# Qorvo_SVD register map
Vendor: Qorvo Inc; Series: ARMCM4; File version: 1.0
Registers are 8-bit, read-write, reset 0x0 unless marked. A register's access mark holds for its fields unless they carry their own. Offsets are from the block's base; [hi:lo] are bit positions; {n}, {i} and the like mark numbered series.

## INT_CTRL
Base 0x40000B00
0x00 INT_CTRL_GLOBAL_INTERRUPTS_ENABLE
  [0] GLOBAL_INTERRUPTS_ENABLE — This bit enables the external interrupts
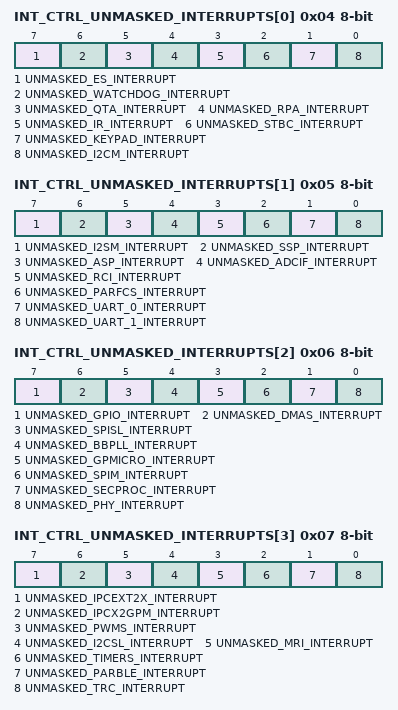
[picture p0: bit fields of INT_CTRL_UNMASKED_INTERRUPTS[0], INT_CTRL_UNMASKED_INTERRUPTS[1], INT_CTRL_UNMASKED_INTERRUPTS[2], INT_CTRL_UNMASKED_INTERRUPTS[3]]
0x04 INT_CTRL_UNMASKED_INTERRUPTS[0] ro
  [7] UNMASKED_ES_INTERRUPT
  [6] UNMASKED_WATCHDOG_INTERRUPT
  [5] UNMASKED_QTA_INTERRUPT — unmasked qta interrupt (same for internal and external)
  [4] UNMASKED_RPA_INTERRUPT — unmasked RPA accelerator interrupt
  [3] UNMASKED_IR_INTERRUPT — unmasked IR driver interrupt
  [2] UNMASKED_STBC_INTERRUPT — unmasked standby controller interrupt (internal and external are the same)
  [1] UNMASKED_KEYPAD_INTERRUPT — unmasked KeyPad Scan interrupt
  [0] UNMASKED_I2CM_INTERRUPT — unmasked I2C master interrupt
0x05 INT_CTRL_UNMASKED_INTERRUPTS[1] ro
  [7] UNMASKED_I2SM_INTERRUPT — unmasked I2S master interrupt
  [6] UNMASKED_SSP_INTERRUPT — unmasked security processor interrupt
  [5] UNMASKED_ASP_INTERRUPT — unmasked ASP interface interrupt
  [4] UNMASKED_ADCIF_INTERRUPT — unmasked ADC interface interrupt
  [3] UNMASKED_RCI_INTERRUPT
  [2] UNMASKED_PARFCS_INTERRUPT — unmasked parfcs filter interrupt (same for internal and external)
  [1] UNMASKED_UART_0_INTERRUPT — unmasked UART interrupt
  [0] UNMASKED_UART_1_INTERRUPT — unmasked UART interrupt
0x06 INT_CTRL_UNMASKED_INTERRUPTS[2] ro
  [7] UNMASKED_GPIO_INTERRUPT — unmasked gpio external interrupt
  [6] UNMASKED_DMAS_INTERRUPT — unmasked DMA SCB engine interrupt
  [5] UNMASKED_SPISL_INTERRUPT — unmasked SPI Slave interrupt
  [4] UNMASKED_BBPLL_INTERRUPT
  [3] UNMASKED_GPMICRO_INTERRUPT
  [2] UNMASKED_SPIM_INTERRUPT — unmasked SPI Master interrupt
  [1] UNMASKED_SECPROC_INTERRUPT — unmasked Security Processor interrupt
  [0] UNMASKED_PHY_INTERRUPT
0x07 INT_CTRL_UNMASKED_INTERRUPTS[3] ro
  [7] UNMASKED_IPCEXT2X_INTERRUPT — unmasked inter process communication interrupt (ext 2 ...)
  [6] UNMASKED_IPCX2GPM_INTERRUPT — unmasked inter process communication interrupt (... 2 gpm)
  [5] UNMASKED_PWMS_INTERRUPT — unmasked PWM interrupt
  [4] UNMASKED_I2CSL_INTERRUPT — unmasked I2C Slave interrupt
  [3] UNMASKED_MRI_INTERRUPT — unmasked mri interrupt (internal and external are the same)
  [2] UNMASKED_TIMERS_INTERRUPT — unmasked timer interrupt
  [1] UNMASKED_PARBLE_INTERRUPT — unmasked parble filter interrupt (same for internal and external)
  [0] UNMASKED_TRC_INTERRUPT — unmasked trc interrupt (same for internal and external)
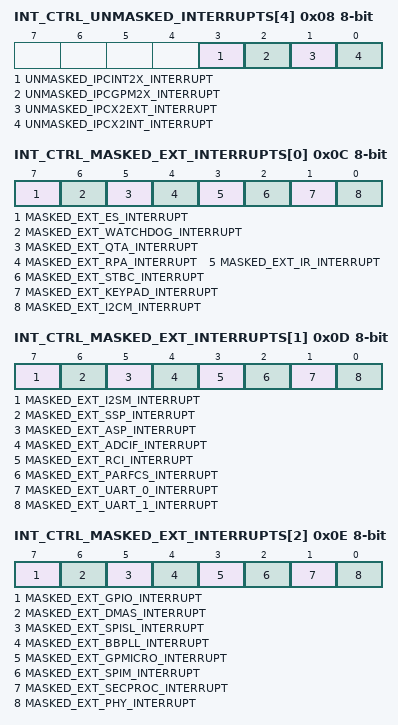
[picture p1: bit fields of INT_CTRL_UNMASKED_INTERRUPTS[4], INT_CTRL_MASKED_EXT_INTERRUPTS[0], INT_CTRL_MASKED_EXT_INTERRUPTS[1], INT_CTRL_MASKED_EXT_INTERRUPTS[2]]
0x08 INT_CTRL_UNMASKED_INTERRUPTS[4] ro
  [3] UNMASKED_IPCINT2X_INTERRUPT — unmasked inter process communication interrupt (int 2 ...)
  [2] UNMASKED_IPCGPM2X_INTERRUPT — unmasked inter process communication interrupt (gpm 2 ...)
  [1] UNMASKED_IPCX2EXT_INTERRUPT — unmasked inter process communication interrupt (... 2 ext)
  [0] UNMASKED_IPCX2INT_INTERRUPT — unmasked inter process communication interrupt (... 2 int)
0x0C INT_CTRL_MASKED_EXT_INTERRUPTS[0] ro
  [7] MASKED_EXT_ES_INTERRUPT — masked external ES interrupt
  [6] MASKED_EXT_WATCHDOG_INTERRUPT — masked external watchdog interrupt
  [5] MASKED_EXT_QTA_INTERRUPT — masked external qta interrupt (same for internal and external)
  [4] MASKED_EXT_RPA_INTERRUPT — masked external RPA accelerator interrupt
  [3] MASKED_EXT_IR_INTERRUPT — masked external IR driver interrupt
  [2] MASKED_EXT_STBC_INTERRUPT — masked external standby controller interrupt (internal and external are the same)
  [1] MASKED_EXT_KEYPAD_INTERRUPT — masked external KeyPad Scan interrupt
  [0] MASKED_EXT_I2CM_INTERRUPT — masked external I2C master interrupt
0x0D INT_CTRL_MASKED_EXT_INTERRUPTS[1] ro
  [7] MASKED_EXT_I2SM_INTERRUPT — masked external I2S master interrupt
  [6] MASKED_EXT_SSP_INTERRUPT — masked external security processor interrupt
  [5] MASKED_EXT_ASP_INTERRUPT — masked external ASP interface interrupt
  [4] MASKED_EXT_ADCIF_INTERRUPT — masked external ADC interface interrupt
  [3] MASKED_EXT_RCI_INTERRUPT — masked external RCI interrupt
  [2] MASKED_EXT_PARFCS_INTERRUPT — masked external parfcs filter interrupt (same for internal and external)
  [1] MASKED_EXT_UART_0_INTERRUPT — masked external UART interrupt
  [0] MASKED_EXT_UART_1_INTERRUPT — masked external UART interrupt
0x0E INT_CTRL_MASKED_EXT_INTERRUPTS[2] ro
  [7] MASKED_EXT_GPIO_INTERRUPT — masked external gpio external interrupt
  [6] MASKED_EXT_DMAS_INTERRUPT — masked external DMA SCB engine interrupt
  [5] MASKED_EXT_SPISL_INTERRUPT — masked external SPI Slave interrupt
  [4] MASKED_EXT_BBPLL_INTERRUPT — masked external BBPLL interrupt
  [3] MASKED_EXT_GPMICRO_INTERRUPT — masked external gpmicro interrupt
  [2] MASKED_EXT_SPIM_INTERRUPT — masked external SPI Master interrupt
  [1] MASKED_EXT_SECPROC_INTERRUPT — masked external Security Processor interrupt
  [0] MASKED_EXT_PHY_INTERRUPT — masked external Phy interrupt
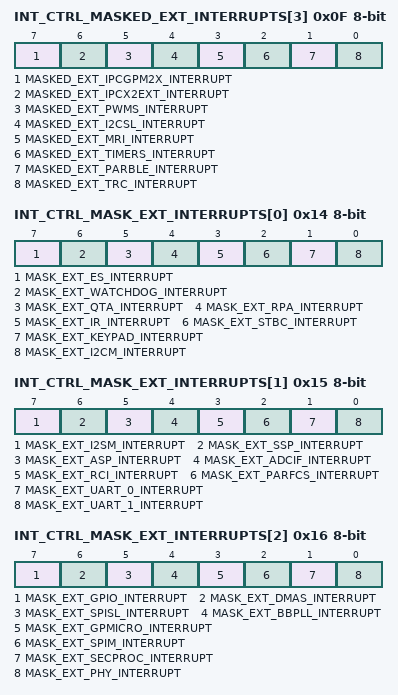
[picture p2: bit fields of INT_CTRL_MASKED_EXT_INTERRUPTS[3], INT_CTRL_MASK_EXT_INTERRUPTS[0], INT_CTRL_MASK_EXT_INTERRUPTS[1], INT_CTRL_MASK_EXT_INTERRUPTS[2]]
0x0F INT_CTRL_MASKED_EXT_INTERRUPTS[3] ro
  [7] MASKED_EXT_IPCGPM2X_INTERRUPT — masked external inter process communication interrupt (gpm 2 ...)
  [6] MASKED_EXT_IPCX2EXT_INTERRUPT — masked external inter process communication interrupt (... 2 ext)
  [5] MASKED_EXT_PWMS_INTERRUPT — masked external PWM interrupt
  [4] MASKED_EXT_I2CSL_INTERRUPT — masked external I2C Slave interrupt
  [3] MASKED_EXT_MRI_INTERRUPT — masked external mri interrupt (internal and external are the same)
  [2] MASKED_EXT_TIMERS_INTERRUPT — masked external timer interrupt
  [1] MASKED_EXT_PARBLE_INTERRUPT — masked external parble filter interrupt (same for internal and external)
  [0] MASKED_EXT_TRC_INTERRUPT — masked external trc interrupt (same for internal and external)
0x10 INT_CTRL_MASKED_EXT_INTERRUPTS[4] ro
  [0] MASKED_EXT_IPCINT2X_INTERRUPT — masked external inter process communication interrupt (int 2 ...)
0x14 INT_CTRL_MASK_EXT_INTERRUPTS[0]
  [7] MASK_EXT_ES_INTERRUPT — mask external ES interrupt
  [6] MASK_EXT_WATCHDOG_INTERRUPT — mask external watchdog interrupt
  [5] MASK_EXT_QTA_INTERRUPT — mask external qta interrupt (same for internal and external)
  [4] MASK_EXT_RPA_INTERRUPT — mask external RPA accelerator interrupt
  [3] MASK_EXT_IR_INTERRUPT — mask external IR driver interrupt
  [2] MASK_EXT_STBC_INTERRUPT — mask external standby controller interrupt (internal and external are the same)
  [1] MASK_EXT_KEYPAD_INTERRUPT — mask external KeyPad Scan interrupt
  [0] MASK_EXT_I2CM_INTERRUPT — mask external I2C master interrupt
0x15 INT_CTRL_MASK_EXT_INTERRUPTS[1]
  [7] MASK_EXT_I2SM_INTERRUPT — mask external I2S master interrupt
  [6] MASK_EXT_SSP_INTERRUPT — mask external security processor interrupt
  [5] MASK_EXT_ASP_INTERRUPT — mask external ASP interface interrupt
  [4] MASK_EXT_ADCIF_INTERRUPT — mask external ADC interface interrupt
  [3] MASK_EXT_RCI_INTERRUPT — mask external RCI interrupt
  [2] MASK_EXT_PARFCS_INTERRUPT — mask external parfcs filter interrupt (same for internal and external)
  [1] MASK_EXT_UART_0_INTERRUPT — mask external UART interrupt
  [0] MASK_EXT_UART_1_INTERRUPT — mask external UART interrupt
0x16 INT_CTRL_MASK_EXT_INTERRUPTS[2]
  [7] MASK_EXT_GPIO_INTERRUPT — mask external gpio external interrupt
  [6] MASK_EXT_DMAS_INTERRUPT — mask external DMA SCB engine interrupt
  [5] MASK_EXT_SPISL_INTERRUPT — mask external SPI Slave interrupt
  [4] MASK_EXT_BBPLL_INTERRUPT — mask external BBPLL interrupt
  [3] MASK_EXT_GPMICRO_INTERRUPT — mask external gpmicro interrupt
  [2] MASK_EXT_SPIM_INTERRUPT — mask external SPI Master interrupt
  [1] MASK_EXT_SECPROC_INTERRUPT — mask external Security Processor interrupt
  [0] MASK_EXT_PHY_INTERRUPT — mask external Phy interrupt
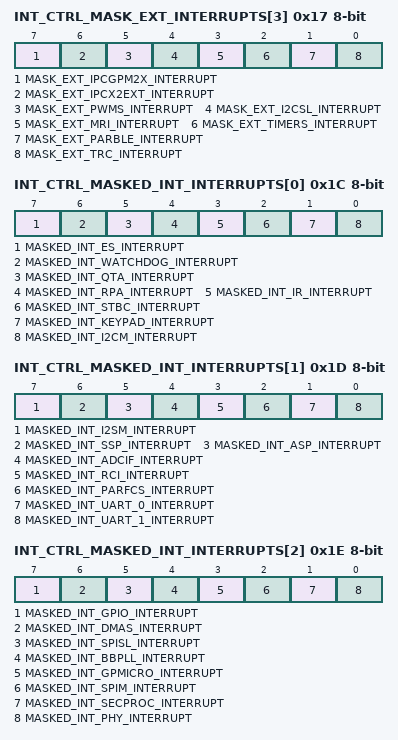
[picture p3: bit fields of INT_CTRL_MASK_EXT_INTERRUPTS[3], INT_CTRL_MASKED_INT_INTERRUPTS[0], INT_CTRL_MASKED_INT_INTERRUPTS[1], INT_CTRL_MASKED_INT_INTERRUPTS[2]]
0x17 INT_CTRL_MASK_EXT_INTERRUPTS[3]
  [7] MASK_EXT_IPCGPM2X_INTERRUPT — mask external inter process communication interrupt (gpm 2 ...)
  [6] MASK_EXT_IPCX2EXT_INTERRUPT — mask external inter process communication interrupt (... 2 ext)
  [5] MASK_EXT_PWMS_INTERRUPT — mask external PWM interrupt
  [4] MASK_EXT_I2CSL_INTERRUPT — mask external I2C Slave interrupt
  [3] MASK_EXT_MRI_INTERRUPT — mask external mri interrupt (internal and external are the same)
  [2] MASK_EXT_TIMERS_INTERRUPT — mask external timer interrupt
  [1] MASK_EXT_PARBLE_INTERRUPT — mask external parble filter interrupt (same for internal and external)
  [0] MASK_EXT_TRC_INTERRUPT — mask external trc interrupt (same for internal and external)
0x18 INT_CTRL_MASK_EXT_INTERRUPTS[4]
  [0] MASK_EXT_IPCINT2X_INTERRUPT — mask external inter process communication interrupt (int 2 ...)
0x1C INT_CTRL_MASKED_INT_INTERRUPTS[0] ro
  [7] MASKED_INT_ES_INTERRUPT — masked internal ES interrupt
  [6] MASKED_INT_WATCHDOG_INTERRUPT — masked internal watchdog interrupt
  [5] MASKED_INT_QTA_INTERRUPT — masked internal qta interrupt (same for internal and external)
  [4] MASKED_INT_RPA_INTERRUPT — masked internal RPA accelerator interrupt
  [3] MASKED_INT_IR_INTERRUPT — masked internal IR driver interrupt
  [2] MASKED_INT_STBC_INTERRUPT — masked internal standby controller interrupt (internal and external are the same)
  [1] MASKED_INT_KEYPAD_INTERRUPT — masked internal KeyPad Scan interrupt
  [0] MASKED_INT_I2CM_INTERRUPT — masked internal I2C master interrupt
0x1D INT_CTRL_MASKED_INT_INTERRUPTS[1] ro
  [7] MASKED_INT_I2SM_INTERRUPT — masked internal I2S master interrupt
  [6] MASKED_INT_SSP_INTERRUPT — masked internal security processor interrupt
  [5] MASKED_INT_ASP_INTERRUPT — masked internal ASP interface interrupt
  [4] MASKED_INT_ADCIF_INTERRUPT — masked internal ADC interface interrupt
  [3] MASKED_INT_RCI_INTERRUPT — masked internal RCI interrupt
  [2] MASKED_INT_PARFCS_INTERRUPT — masked internal parfcs filter interrupt (same for internal and external)
  [1] MASKED_INT_UART_0_INTERRUPT — masked internal UART interrupt
  [0] MASKED_INT_UART_1_INTERRUPT — masked internal UART interrupt
0x1E INT_CTRL_MASKED_INT_INTERRUPTS[2] ro
  [7] MASKED_INT_GPIO_INTERRUPT — masked internal gpio external interrupt
  [6] MASKED_INT_DMAS_INTERRUPT — masked internal DMA SCB engine interrupt
  [5] MASKED_INT_SPISL_INTERRUPT — masked internal SPI Slave interrupt
  [4] MASKED_INT_BBPLL_INTERRUPT — masked internal BBPLL interrupt
  [3] MASKED_INT_GPMICRO_INTERRUPT — masked internal gpmicro interrupt
  [2] MASKED_INT_SPIM_INTERRUPT — masked internal SPI Master interrupt
  [1] MASKED_INT_SECPROC_INTERRUPT — masked internal Security Processor interrupt
  [0] MASKED_INT_PHY_INTERRUPT — masked internal Phy interrupt
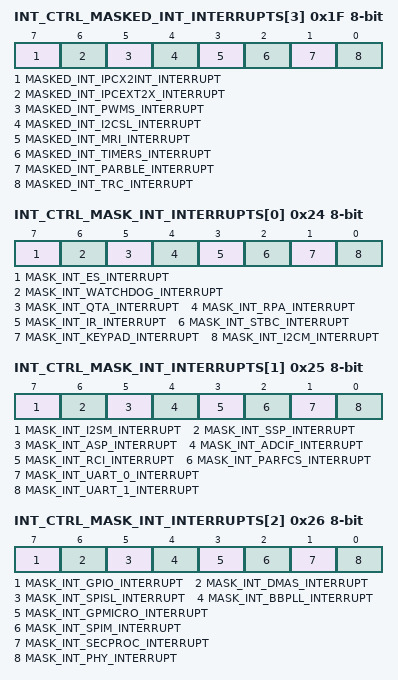
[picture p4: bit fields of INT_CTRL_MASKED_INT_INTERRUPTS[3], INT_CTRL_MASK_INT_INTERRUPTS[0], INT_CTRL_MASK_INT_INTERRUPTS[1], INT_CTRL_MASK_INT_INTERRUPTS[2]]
0x1F INT_CTRL_MASKED_INT_INTERRUPTS[3] ro
  [7] MASKED_INT_IPCX2INT_INTERRUPT — masked internal inter process communication interrupt (... 2 int)
  [6] MASKED_INT_IPCEXT2X_INTERRUPT — masked internal inter process communication interrupt (ext 2 ...)
  [5] MASKED_INT_PWMS_INTERRUPT — masked internal PWM interrupt
  [4] MASKED_INT_I2CSL_INTERRUPT — masked internal I2C Slave interrupt
  [3] MASKED_INT_MRI_INTERRUPT — masked internal mri interrupt (internal and external are the same)
  [2] MASKED_INT_TIMERS_INTERRUPT — masked internal timer interrupt
  [1] MASKED_INT_PARBLE_INTERRUPT — masked internal parble filter interrupt (same for internal and external)
  [0] MASKED_INT_TRC_INTERRUPT — masked internal trc interrupt (same for internal and external)
0x20 INT_CTRL_MASKED_INT_INTERRUPTS[4] ro
  [0] MASKED_INT_IPCGPM2X_INTERRUPT — masked internal inter process communication interrupt (gpm 2 ...)
0x24 INT_CTRL_MASK_INT_INTERRUPTS[0]
  [7] MASK_INT_ES_INTERRUPT — mask internal ES interrupt
  [6] MASK_INT_WATCHDOG_INTERRUPT — mask internal watchdog interrupt
  [5] MASK_INT_QTA_INTERRUPT — mask internal qta interrupt (same for internal and external)
  [4] MASK_INT_RPA_INTERRUPT — mask internal RPA accelerator interrupt
  [3] MASK_INT_IR_INTERRUPT — mask internal IR driver interrupt
  [2] MASK_INT_STBC_INTERRUPT — mask internal standby controller interrupt (internal and external are the same)
  [1] MASK_INT_KEYPAD_INTERRUPT — mask internal KeyPad Scan interrupt
  [0] MASK_INT_I2CM_INTERRUPT — mask internal I2C master interrupt
0x25 INT_CTRL_MASK_INT_INTERRUPTS[1]
  [7] MASK_INT_I2SM_INTERRUPT — mask internal I2S master interrupt
  [6] MASK_INT_SSP_INTERRUPT — mask internal security processor interrupt
  [5] MASK_INT_ASP_INTERRUPT — mask internal ASP interface interrupt
  [4] MASK_INT_ADCIF_INTERRUPT — mask internal ADC interface interrupt
  [3] MASK_INT_RCI_INTERRUPT — mask internal RCI interrupt
  [2] MASK_INT_PARFCS_INTERRUPT — mask internal parfcs filter interrupt (same for internal and external)
  [1] MASK_INT_UART_0_INTERRUPT — mask internal UART interrupt
  [0] MASK_INT_UART_1_INTERRUPT — mask internal UART interrupt
0x26 INT_CTRL_MASK_INT_INTERRUPTS[2]
  [7] MASK_INT_GPIO_INTERRUPT — mask internal gpio external interrupt
  [6] MASK_INT_DMAS_INTERRUPT — mask internal DMA SCB engine interrupt
  [5] MASK_INT_SPISL_INTERRUPT — mask internal SPI Slave interrupt
  [4] MASK_INT_BBPLL_INTERRUPT — mask internal BBPLL interrupt
  [3] MASK_INT_GPMICRO_INTERRUPT — mask internal gpmicro interrupt
  [2] MASK_INT_SPIM_INTERRUPT — mask internal SPI Master interrupt
  [1] MASK_INT_SECPROC_INTERRUPT — mask internal Security Processor interrupt
  [0] MASK_INT_PHY_INTERRUPT — mask internal Phy interrupt
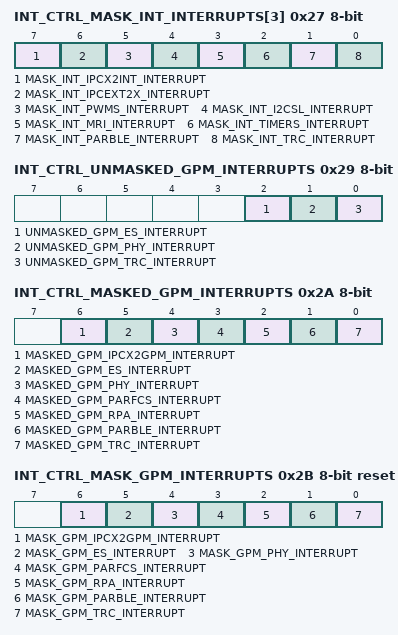
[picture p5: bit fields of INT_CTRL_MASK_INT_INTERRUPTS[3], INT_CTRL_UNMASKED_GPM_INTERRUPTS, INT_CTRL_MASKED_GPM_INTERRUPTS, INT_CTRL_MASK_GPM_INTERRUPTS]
0x27 INT_CTRL_MASK_INT_INTERRUPTS[3]
  [7] MASK_INT_IPCX2INT_INTERRUPT — mask internal inter process communication interrupt (... 2 int)
  [6] MASK_INT_IPCEXT2X_INTERRUPT — mask internal inter process communication interrupt (ext 2 ...)
  [5] MASK_INT_PWMS_INTERRUPT — mask internal PWM interrupt
  [4] MASK_INT_I2CSL_INTERRUPT — mask internal I2C Slave interrupt
  [3] MASK_INT_MRI_INTERRUPT — mask internal mri interrupt (internal and external are the same)
  [2] MASK_INT_TIMERS_INTERRUPT — mask internal timer interrupt
  [1] MASK_INT_PARBLE_INTERRUPT — mask internal parble filter interrupt (same for internal and external)
  [0] MASK_INT_TRC_INTERRUPT — mask internal trc interrupt (same for internal and external)
0x28 INT_CTRL_MASK_INT_INTERRUPTS[4]
  [0] MASK_INT_IPCGPM2X_INTERRUPT — mask internal inter process communication interrupt (gpm 2 ...)
0x29 INT_CTRL_UNMASKED_GPM_INTERRUPTS ro
  [2] UNMASKED_GPM_ES_INTERRUPT — unmasked ES interrupt for gpmicro
  [1] UNMASKED_GPM_PHY_INTERRUPT — unmasked Phy interrupt for gpmicro
  [0] UNMASKED_GPM_TRC_INTERRUPT — unmasked trc interrupt for gpmicro
0x2A INT_CTRL_MASKED_GPM_INTERRUPTS ro
  [6] MASKED_GPM_IPCX2GPM_INTERRUPT — masked inter process communication interrupt (... 2 gpm) for gpmicro
  [5] MASKED_GPM_ES_INTERRUPT — masked ES interrupt for gpmicro
  [4] MASKED_GPM_PHY_INTERRUPT — masked Phy interrupt for gpmicro
  [3] MASKED_GPM_PARFCS_INTERRUPT — masked parfcs filter interrupt for gpmicro
  [2] MASKED_GPM_RPA_INTERRUPT — masked RPA accelerator interrupt for gpmicro
  [1] MASKED_GPM_PARBLE_INTERRUPT — masked parble filter interrupt for gpmicro
  [0] MASKED_GPM_TRC_INTERRUPT — masked trc interrupt for gpmicro
0x2B INT_CTRL_MASK_GPM_INTERRUPTS reset 0x1A
  [6] MASK_GPM_IPCX2GPM_INTERRUPT — mask inter process communication interrupt (... 2 gpm) for gpmicro
  [5] MASK_GPM_ES_INTERRUPT — mask ES interrupt for gpmicro
  [4] MASK_GPM_PHY_INTERRUPT — mask Phy interrupt for gpmicro
  [3] MASK_GPM_PARFCS_INTERRUPT — mask parfcs filter interrupt for gpmicro
  [2] MASK_GPM_RPA_INTERRUPT — mask RPA accelerator interrupt for gpmicro
  [1] MASK_GPM_PARBLE_INTERRUPT — mask parble filter interrupt for gpmicro
  [0] MASK_GPM_TRC_INTERRUPT — mask trc interrupt for gpmicro
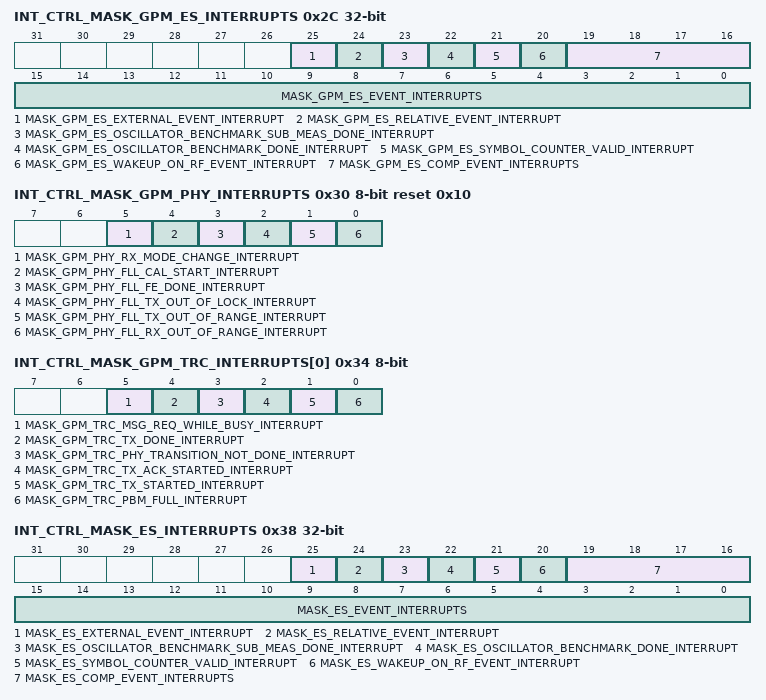
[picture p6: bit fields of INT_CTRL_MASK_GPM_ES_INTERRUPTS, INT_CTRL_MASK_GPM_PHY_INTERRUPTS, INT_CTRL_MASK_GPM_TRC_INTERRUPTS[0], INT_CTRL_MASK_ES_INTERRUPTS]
0x2C INT_CTRL_MASK_GPM_ES_INTERRUPTS 32-bit
  [25] MASK_GPM_ES_EXTERNAL_EVENT_INTERRUPT — masks the External Event Interrupt
  [24] MASK_GPM_ES_RELATIVE_EVENT_INTERRUPT — masks the es Relative Event Interrupt
  [23] MASK_GPM_ES_OSCILLATOR_BENCHMARK_SUB_MEAS_DONE_INTERRUPT — masks the es oscillator benchmark sub measurement done interrupt
  [22] MASK_GPM_ES_OSCILLATOR_BENCHMARK_DONE_INTERRUPT — masks the es oscillator benchmark interrupt
  [21] MASK_GPM_ES_SYMBOL_COUNTER_VALID_INTERRUPT — masks the es symbol counter interrupt
  [20] MASK_GPM_ES_WAKEUP_ON_RF_EVENT_INTERRUPT — masks the Wakeup_on_rf Event interrupt
  [19:16] MASK_GPM_ES_COMP_EVENT_INTERRUPTS — masks the Comparator Event interrupts
  [15:0] MASK_GPM_ES_EVENT_INTERRUPTS — masks the Event Interrupts
0x30 INT_CTRL_MASK_GPM_PHY_INTERRUPTS reset 0x10
  [5] MASK_GPM_PHY_RX_MODE_CHANGE_INTERRUPT — masks the interrupt for rx_mode changes
  [4] MASK_GPM_PHY_FLL_CAL_START_INTERRUPT — masks the interrupt for the fll fp out of range event
  [3] MASK_GPM_PHY_FLL_FE_DONE_INTERRUPT — masks the interrupt for the fll fp out of range event
  [2] MASK_GPM_PHY_FLL_TX_OUT_OF_LOCK_INTERRUPT — masks the interrupt for the fll tx_out of lock event
  [1] MASK_GPM_PHY_FLL_TX_OUT_OF_RANGE_INTERRUPT — masks the interrupt for the fll tx out of range event
  [0] MASK_GPM_PHY_FLL_RX_OUT_OF_RANGE_INTERRUPT — masks the interrupt for the fll rx out of range event
0x34 INT_CTRL_MASK_GPM_TRC_INTERRUPTS[0]
  [5] MASK_GPM_TRC_MSG_REQ_WHILE_BUSY_INTERRUPT, [4] MASK_GPM_TRC_TX_DONE_INTERRUPT, [3] MASK_GPM_TRC_PHY_TRANSITION_NOT_DONE_INTERRUPT, [2] MASK_GPM_TRC_TX_ACK_STARTED_INTERRUPT, [1] MASK_GPM_TRC_TX_STARTED_INTERRUPT, [0] MASK_GPM_TRC_PBM_FULL_INTERRUPT
0x35 INT_CTRL_MASK_GPM_TRC_INTERRUPTS[1]
  [n] MASK_GPM_TRC_CAL_DONE_CH{n}_INTERRUPT (n=0..5), [5:0] MASK_GPM_TRC_CAL_DONE_INTERRUPTS
0x36 INT_CTRL_MASK_GPM_TRC_INTERRUPTS[2]
  [n] MASK_GPM_TRC_RX_WINDOW_DONE_CH{n}_INTERRUPT (n=0..5), [5:0] MASK_GPM_TRC_RX_WINDOW_DONE_INTERRUPTS
0x38 INT_CTRL_MASK_ES_INTERRUPTS 32-bit
  [25] MASK_ES_EXTERNAL_EVENT_INTERRUPT — masks the External Event Interrupt
  [24] MASK_ES_RELATIVE_EVENT_INTERRUPT — masks the es Relative Event Interrupt
  [23] MASK_ES_OSCILLATOR_BENCHMARK_SUB_MEAS_DONE_INTERRUPT — masks the es oscillator benchmark sub meas done interrupt
  [22] MASK_ES_OSCILLATOR_BENCHMARK_DONE_INTERRUPT — masks the es oscillator benchmark interrupt
  [21] MASK_ES_SYMBOL_COUNTER_VALID_INTERRUPT — masks the es symbol counter interrupt
  [20] MASK_ES_WAKEUP_ON_RF_EVENT_INTERRUPT — masks the Wakeup_on_rf Event interrupt
  [19:16] MASK_ES_COMP_EVENT_INTERRUPTS — masks the Comparator Event interrupts
  [15:0] MASK_ES_EVENT_INTERRUPTS — masks the Event Interrupts
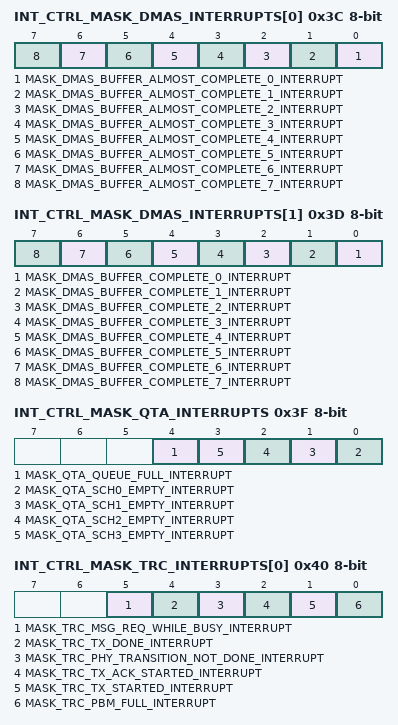
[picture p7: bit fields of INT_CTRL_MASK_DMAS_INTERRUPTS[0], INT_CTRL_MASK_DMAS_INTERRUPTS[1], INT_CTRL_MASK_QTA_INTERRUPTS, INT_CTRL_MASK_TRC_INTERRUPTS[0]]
0x3C INT_CTRL_MASK_DMAS_INTERRUPTS[0]
  [n] MASK_DMAS_BUFFER_ALMOST_COMPLETE_{n}_INTERRUPT (n=0..7)
0x3D INT_CTRL_MASK_DMAS_INTERRUPTS[1]
  [n] MASK_DMAS_BUFFER_COMPLETE_{n}_INTERRUPT (n=0..7)
0x3E INT_CTRL_MASK_DMAS_INTERRUPTS[2]
  [0] MASK_DMAS_CPY_ERR_INTERRUPT
0x3F INT_CTRL_MASK_QTA_INTERRUPTS
  [4] MASK_QTA_QUEUE_FULL_INTERRUPT, [n] MASK_QTA_SCH{n}_EMPTY_INTERRUPT (n=0..3)
0x40 INT_CTRL_MASK_TRC_INTERRUPTS[0]
  [5] MASK_TRC_MSG_REQ_WHILE_BUSY_INTERRUPT, [4] MASK_TRC_TX_DONE_INTERRUPT, [3] MASK_TRC_PHY_TRANSITION_NOT_DONE_INTERRUPT, [2] MASK_TRC_TX_ACK_STARTED_INTERRUPT, [1] MASK_TRC_TX_STARTED_INTERRUPT, [0] MASK_TRC_PBM_FULL_INTERRUPT
0x41 INT_CTRL_MASK_TRC_INTERRUPTS[1]
  [n] MASK_TRC_CAL_DONE_CH{n}_INTERRUPT (n=0..5), [5:0] MASK_TRC_CAL_DONE_INTERRUPTS
0x42 INT_CTRL_MASK_TRC_INTERRUPTS[2]
  [n] MASK_TRC_RX_WINDOW_DONE_CH{n}_INTERRUPT (n=0..5), [5:0] MASK_TRC_RX_WINDOW_DONE_INTERRUPTS
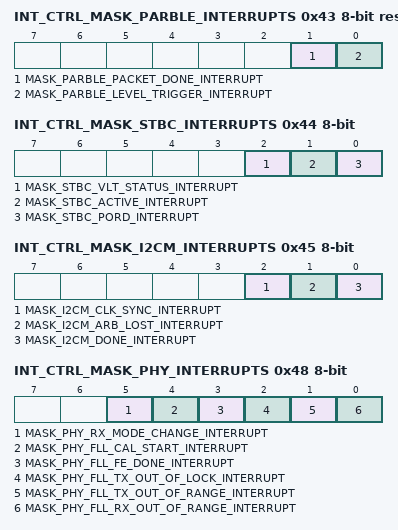
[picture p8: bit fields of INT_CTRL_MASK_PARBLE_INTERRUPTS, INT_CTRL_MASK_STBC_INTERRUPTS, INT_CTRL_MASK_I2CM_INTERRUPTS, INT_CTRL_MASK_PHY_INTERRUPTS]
0x43 INT_CTRL_MASK_PARBLE_INTERRUPTS reset 0x1
  [1] MASK_PARBLE_PACKET_DONE_INTERRUPT
  [0] MASK_PARBLE_LEVEL_TRIGGER_INTERRUPT — triggering an interrupt when n bytes were received
0x44 INT_CTRL_MASK_STBC_INTERRUPTS
  [2] MASK_STBC_VLT_STATUS_INTERRUPT — masks the standby controller vlt_status interrupt
  [1] MASK_STBC_ACTIVE_INTERRUPT — masks the standby controller Active state interrupt
  [0] MASK_STBC_PORD_INTERRUPT — masks the standby controller event power on reset detected interrupt
0x45 INT_CTRL_MASK_I2CM_INTERRUPTS
  [2] MASK_I2CM_CLK_SYNC_INTERRUPT — masks the I2C master clock synchronization slave wait interrupt
  [1] MASK_I2CM_ARB_LOST_INTERRUPT — masks the I2C master arbitration lost interrupt
  [0] MASK_I2CM_DONE_INTERRUPT — masks the I2C master done interrupt
0x46 INT_CTRL_MASK_RCI_INTERRUPTS 16-bit
  [9] MASK_RCI_BLE_DATA_CNF_INTERRUPT, [8] MASK_RCI_BLE_CONN_RSP_IND_INTERRUPT, [7] MASK_RCI_BLE_CONN_REQ_IND_INTERRUPT, [6] MASK_RCI_BLE_ADV_IND_INTERRUPT, [5] MASK_RCI_BLE_DATA_IND_INTERRUPT, [n+1] MASK_RCI_DATA_CNF_{n}_INTERRUPT (n=0..3), [4:1] MASK_RCI_DATA_CNF_INTERRUPTS, [0] MASK_RCI_DATA_IND_INTERRUPT
0x48 INT_CTRL_MASK_PHY_INTERRUPTS
  [5] MASK_PHY_RX_MODE_CHANGE_INTERRUPT — masks the interrupt for rx_mode changes
  [4] MASK_PHY_FLL_CAL_START_INTERRUPT — masks the interrupt for the fll fp out of range event
  [3] MASK_PHY_FLL_FE_DONE_INTERRUPT — masks the interrupt for the fll fp out of range event
  [2] MASK_PHY_FLL_TX_OUT_OF_LOCK_INTERRUPT — masks the interrupt for the fll tx_out of lock event
  [1] MASK_PHY_FLL_TX_OUT_OF_RANGE_INTERRUPT — masks the interrupt for the fll tx out of range event
  [0] MASK_PHY_FLL_RX_OUT_OF_RANGE_INTERRUPT — masks the interrupt for the fll rx out of range event
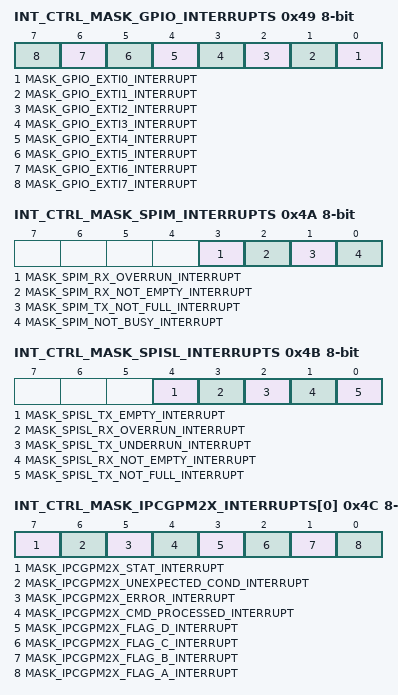
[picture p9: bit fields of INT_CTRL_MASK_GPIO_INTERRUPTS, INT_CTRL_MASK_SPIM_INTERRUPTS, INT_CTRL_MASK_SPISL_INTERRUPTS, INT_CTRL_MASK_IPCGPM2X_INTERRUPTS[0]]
0x49 INT_CTRL_MASK_GPIO_INTERRUPTS
  [n] MASK_GPIO_EXTI{n}_INTERRUPT (n=0..7) — masks the gpio interrupts for exti {n} of the selected port
0x4A INT_CTRL_MASK_SPIM_INTERRUPTS
  [3] MASK_SPIM_RX_OVERRUN_INTERRUPT — masks the SPI master RX buffer overrun interrupt
  [2] MASK_SPIM_RX_NOT_EMPTY_INTERRUPT — masks the SPI master RX buffer not empty interrupt
  [1] MASK_SPIM_TX_NOT_FULL_INTERRUPT — masks the SPI master TX buffer empty interrupt
  [0] MASK_SPIM_NOT_BUSY_INTERRUPT — masks the SPI master transfer not busy interrupt
0x4B INT_CTRL_MASK_SPISL_INTERRUPTS
  [4] MASK_SPISL_TX_EMPTY_INTERRUPT — masks the SPI slave TX empty interrupt
  [3] MASK_SPISL_RX_OVERRUN_INTERRUPT — masks the SPI slave RX buffer overrun interrupt
  [2] MASK_SPISL_TX_UNDERRUN_INTERRUPT — masks the SPI slave TX buffer underrun interrupt
  [1] MASK_SPISL_RX_NOT_EMPTY_INTERRUPT — masks the SPI slave RX buffer not empty interrupt
  [0] MASK_SPISL_TX_NOT_FULL_INTERRUPT — masks the SPI slave TX buffer empty interrupt
0x4C INT_CTRL_MASK_IPCGPM2X_INTERRUPTS[0]
  [7] MASK_IPCGPM2X_STAT_INTERRUPT — masks the gpmicro status interrupt
  [6] MASK_IPCGPM2X_UNEXPECTED_COND_INTERRUPT — masks the gpmicro unexpected condition interrupt
  [5] MASK_IPCGPM2X_ERROR_INTERRUPT — masks the gpmicro error interrupt
  [4] MASK_IPCGPM2X_CMD_PROCESSED_INTERRUPT — Indicates that an internal cmd is processed
  [3] MASK_IPCGPM2X_FLAG_D_INTERRUPT — masks the inter processor communication source interrupt (gpm 2 ...)
  [2] MASK_IPCGPM2X_FLAG_C_INTERRUPT — masks the inter processor communication source interrupt (gpm 2 ...)
  [1] MASK_IPCGPM2X_FLAG_B_INTERRUPT — masks the inter processor communication source interrupt (gpm 2 ...)
  [0] MASK_IPCGPM2X_FLAG_A_INTERRUPT — masks the inter processor communication source interrupt (gpm 2 ...)
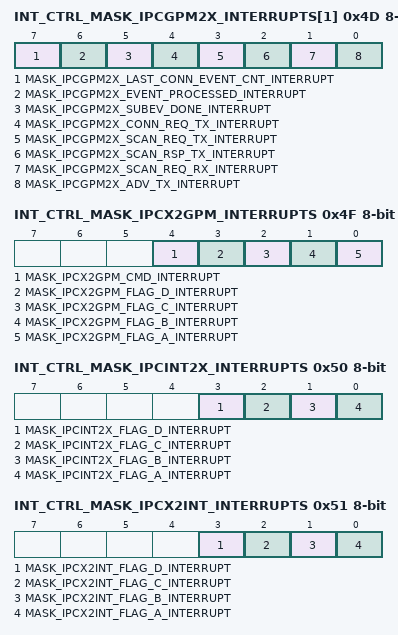
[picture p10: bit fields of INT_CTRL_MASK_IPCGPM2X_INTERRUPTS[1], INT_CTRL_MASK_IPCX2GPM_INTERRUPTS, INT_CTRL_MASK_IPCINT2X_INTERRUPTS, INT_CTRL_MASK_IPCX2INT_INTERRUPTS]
0x4D INT_CTRL_MASK_IPCGPM2X_INTERRUPTS[1]
  [7] MASK_IPCGPM2X_LAST_CONN_EVENT_CNT_INTERRUPT — Indicates that a connection ble event has reached its last_sch_event_cnt (if enabled)
  [6] MASK_IPCGPM2X_EVENT_PROCESSED_INTERRUPT — Indicates that a ble event has been processed
  [5] MASK_IPCGPM2X_SUBEV_DONE_INTERRUPT — Indicates that a subevent has been processed
  [4] MASK_IPCGPM2X_CONN_REQ_TX_INTERRUPT — Indicates that a CONN_REQ frame is sent
  [3] MASK_IPCGPM2X_SCAN_REQ_TX_INTERRUPT — Indicates that a SCAN_REQ frame is sent
  [2] MASK_IPCGPM2X_SCAN_RSP_TX_INTERRUPT — Indicates a scan response is sent
  [1] MASK_IPCGPM2X_SCAN_REQ_RX_INTERRUPT — Indicates a scan request has been received
  [0] MASK_IPCGPM2X_ADV_TX_INTERRUPT — Indicates a frame is sent during an advertising event
0x4E INT_CTRL_MASK_IPCGPM2X_INTERRUPTS[2]
  [0] MASK_IPCGPM2X_EVENT_SKIPPED_INTERRUPT — Indicates that a ble event has been skipped
0x4F INT_CTRL_MASK_IPCX2GPM_INTERRUPTS
  [4] MASK_IPCX2GPM_CMD_INTERRUPT — Indicates that a cmd is available to be processed
  [3] MASK_IPCX2GPM_FLAG_D_INTERRUPT
  [2] MASK_IPCX2GPM_FLAG_C_INTERRUPT
  [1] MASK_IPCX2GPM_FLAG_B_INTERRUPT
  [0] MASK_IPCX2GPM_FLAG_A_INTERRUPT
0x50 INT_CTRL_MASK_IPCINT2X_INTERRUPTS
  [3] MASK_IPCINT2X_FLAG_D_INTERRUPT — masks the inter processor communication source interrupt (int 2 ...)
  [2] MASK_IPCINT2X_FLAG_C_INTERRUPT — masks the inter processor communication source interrupt (int 2 ...)
  [1] MASK_IPCINT2X_FLAG_B_INTERRUPT — masks the inter processor communication source interrupt (int 2 ...)
  [0] MASK_IPCINT2X_FLAG_A_INTERRUPT — masks the inter processor communication source interrupt (int 2 ...)
0x51 INT_CTRL_MASK_IPCX2INT_INTERRUPTS
  [3] MASK_IPCX2INT_FLAG_D_INTERRUPT — masks the inter processor communication source interrupt (... 2 int)
  [2] MASK_IPCX2INT_FLAG_C_INTERRUPT — masks the inter processor communication source interrupt (... 2 int)
  [1] MASK_IPCX2INT_FLAG_B_INTERRUPT — masks the inter processor communication source interrupt (... 2 int)
  [0] MASK_IPCX2INT_FLAG_A_INTERRUPT — masks the inter processor communication source interrupt (... 2 int)
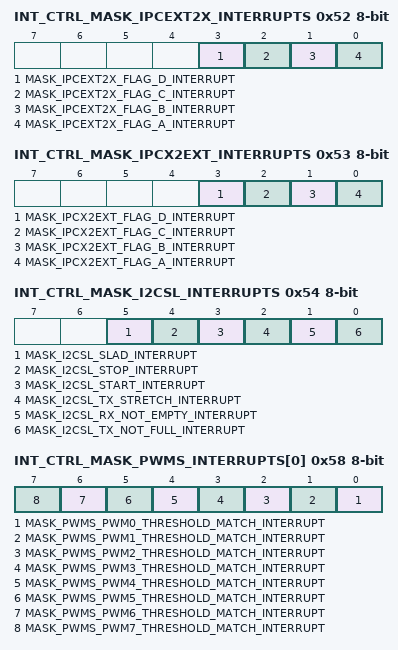
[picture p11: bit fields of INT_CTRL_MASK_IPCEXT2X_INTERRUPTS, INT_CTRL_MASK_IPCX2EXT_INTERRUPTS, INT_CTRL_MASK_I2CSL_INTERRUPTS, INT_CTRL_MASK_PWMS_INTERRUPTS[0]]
0x52 INT_CTRL_MASK_IPCEXT2X_INTERRUPTS
  [3] MASK_IPCEXT2X_FLAG_D_INTERRUPT — masks the inter processor communication source interrupt (ext 2 ...)
  [2] MASK_IPCEXT2X_FLAG_C_INTERRUPT — masks the inter processor communication source interrupt (ext 2 ...)
  [1] MASK_IPCEXT2X_FLAG_B_INTERRUPT — masks the inter processor communication source interrupt (ext 2 ...)
  [0] MASK_IPCEXT2X_FLAG_A_INTERRUPT — masks the inter processor communication source interrupt (ext 2 ...)
0x53 INT_CTRL_MASK_IPCX2EXT_INTERRUPTS
  [3] MASK_IPCX2EXT_FLAG_D_INTERRUPT — masks the inter processor communication source interrupt (... 2 ext)
  [2] MASK_IPCX2EXT_FLAG_C_INTERRUPT — masks the inter processor communication source interrupt (... 2 ext)
  [1] MASK_IPCX2EXT_FLAG_B_INTERRUPT — masks the inter processor communication source interrupt (... 2 ext)
  [0] MASK_IPCX2EXT_FLAG_A_INTERRUPT — masks the inter processor communication source interrupt (... 2 ext)
0x54 INT_CTRL_MASK_I2CSL_INTERRUPTS
  [5] MASK_I2CSL_SLAD_INTERRUPT — masks the I2C SLAD event occurred interrupt
  [4] MASK_I2CSL_STOP_INTERRUPT — masks the I2C STOP event occurred interrupt
  [3] MASK_I2CSL_START_INTERRUPT — masks the I2C START event occurred interrupt
  [2] MASK_I2CSL_TX_STRETCH_INTERRUPT — masks the TX stretch interrupt.
  [1] MASK_I2CSL_RX_NOT_EMPTY_INTERRUPT — masks the RX buffer not empty interrupt
  [0] MASK_I2CSL_TX_NOT_FULL_INTERRUPT — masks the TX buffer not full interrupt.
0x58 INT_CTRL_MASK_PWMS_INTERRUPTS[0]
  [n] MASK_PWMS_PWM{n}_THRESHOLD_MATCH_INTERRUPT (n=0..7) — masks the PWM threshold_match interrupt of pwm{n}
0x59 INT_CTRL_MASK_PWMS_INTERRUPTS[1]
  [7] MASK_PWMS_TIMESTAMP1_NOT_EMPTY_INTERRUPT — masks the PWM timestamp1 not empty interrupt
  [7:6] MASK_PWMS_TIMESTAMP_NOT_EMPTY_INTERRUPT[0] — masks the PWM timestamp not empty interrupt
  [6] MASK_PWMS_TIMESTAMP0_NOT_EMPTY_INTERRUPT — masks the PWM timestamp0 not empty interrupt
  [n+2] MASK_PWMS_TIMESTAMP{n}_OVERRUN_INTERRUPT (n=0..3) — masks the PWM timestamp{n} overrun interrupt
  [5:2] MASK_PWMS_TIMESTAMP_OVERRUN_INTERRUPT — masks the PWM timestamp overrun interrupt
  [1] MASK_PWMS_NEXT_THRESHOLD_NOT_FULL_INTERRUPT — masks the PWM next threshold not full interrupt
  [0] MASK_PWMS_NEXT_THRESHOLD_UNDERRUN_INTERRUPT — masks the PWM next threshold underrun interrupt
0x5A INT_CTRL_MASK_PWMS_INTERRUPTS[2]
  [1] MASK_PWMS_TIMESTAMP3_NOT_EMPTY_INTERRUPT — masks the PWM timestamp3 not empty interrupt
  [1:0] MASK_PWMS_TIMESTAMP_NOT_EMPTY_INTERRUPT[1] — masks the PWM timestamp not empty interrupt
  [0] MASK_PWMS_TIMESTAMP2_NOT_EMPTY_INTERRUPT — masks the PWM timestamp2 not empty interrupt
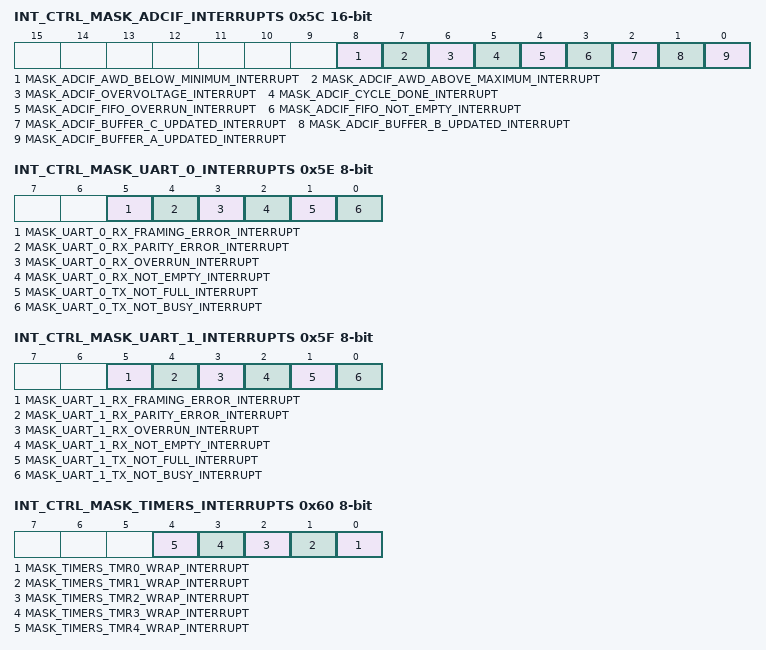
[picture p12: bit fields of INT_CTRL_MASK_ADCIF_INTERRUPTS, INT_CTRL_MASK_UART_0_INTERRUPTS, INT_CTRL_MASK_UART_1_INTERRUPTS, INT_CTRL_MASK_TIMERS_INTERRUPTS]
0x5C INT_CTRL_MASK_ADCIF_INTERRUPTS 16-bit
  [8] MASK_ADCIF_AWD_BELOW_MINIMUM_INTERRUPT — masks the analog watchdog value below minimum interrupt
  [7] MASK_ADCIF_AWD_ABOVE_MAXIMUM_INTERRUPT — masks the analog watchdog value above maximum interrupt
  [6] MASK_ADCIF_OVERVOLTAGE_INTERRUPT — masks the fifo overvoltage interrupt
  [5] MASK_ADCIF_CYCLE_DONE_INTERRUPT — masks the cycle done interrupt
  [4] MASK_ADCIF_FIFO_OVERRUN_INTERRUPT — masks the fifo overrun interrupt
  [3] MASK_ADCIF_FIFO_NOT_EMPTY_INTERRUPT — masks the fifo not empty interrupt
  [2] MASK_ADCIF_BUFFER_C_UPDATED_INTERRUPT — masks the buffer c updated interrupt
  [1] MASK_ADCIF_BUFFER_B_UPDATED_INTERRUPT — masks the buffer b updated interrupt
  [0] MASK_ADCIF_BUFFER_A_UPDATED_INTERRUPT — masks the buffer a updated interrupt
0x5E INT_CTRL_MASK_UART_0_INTERRUPTS
  [5] MASK_UART_0_RX_FRAMING_ERROR_INTERRUPT — masks the RX framing error interrupt.
  [4] MASK_UART_0_RX_PARITY_ERROR_INTERRUPT — masks the RX parity error interrupt.
  [3] MASK_UART_0_RX_OVERRUN_INTERRUPT — masks the RX overrun interrupt.
  [2] MASK_UART_0_RX_NOT_EMPTY_INTERRUPT — masks the RX not empty interrupt.
  [1] MASK_UART_0_TX_NOT_FULL_INTERRUPT — masks the TX not full interrupt.
  [0] MASK_UART_0_TX_NOT_BUSY_INTERRUPT — masks the TX not busy interrupt.
0x5F INT_CTRL_MASK_UART_1_INTERRUPTS
  [5] MASK_UART_1_RX_FRAMING_ERROR_INTERRUPT — masks the RX framing error interrupt.
  [4] MASK_UART_1_RX_PARITY_ERROR_INTERRUPT — masks the RX parity error interrupt.
  [3] MASK_UART_1_RX_OVERRUN_INTERRUPT — masks the RX overrun interrupt.
  [2] MASK_UART_1_RX_NOT_EMPTY_INTERRUPT — masks the RX not empty interrupt.
  [1] MASK_UART_1_TX_NOT_FULL_INTERRUPT — masks the TX not full interrupt.
  [0] MASK_UART_1_TX_NOT_BUSY_INTERRUPT — masks the TX not busy interrupt.
0x60 INT_CTRL_MASK_TIMERS_INTERRUPTS
  [n] MASK_TIMERS_TMR{n}_WRAP_INTERRUPT (n=0..4)
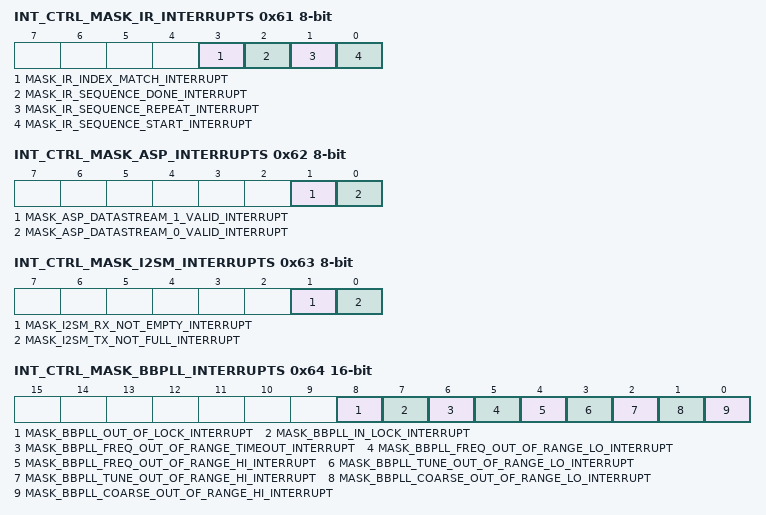
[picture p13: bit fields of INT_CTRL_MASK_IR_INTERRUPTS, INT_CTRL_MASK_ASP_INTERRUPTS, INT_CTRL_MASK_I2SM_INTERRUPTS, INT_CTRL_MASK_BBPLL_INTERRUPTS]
0x61 INT_CTRL_MASK_IR_INTERRUPTS
  [3] MASK_IR_INDEX_MATCH_INTERRUPT, [2] MASK_IR_SEQUENCE_DONE_INTERRUPT, [1] MASK_IR_SEQUENCE_REPEAT_INTERRUPT, [0] MASK_IR_SEQUENCE_START_INTERRUPT
0x62 INT_CTRL_MASK_ASP_INTERRUPTS
  [1] MASK_ASP_DATASTREAM_1_VALID_INTERRUPT, [0] MASK_ASP_DATASTREAM_0_VALID_INTERRUPT
0x63 INT_CTRL_MASK_I2SM_INTERRUPTS
  [1] MASK_I2SM_RX_NOT_EMPTY_INTERRUPT, [0] MASK_I2SM_TX_NOT_FULL_INTERRUPT
0x64 INT_CTRL_MASK_BBPLL_INTERRUPTS 16-bit
  [8] MASK_BBPLL_OUT_OF_LOCK_INTERRUPT, [7] MASK_BBPLL_IN_LOCK_INTERRUPT, [6] MASK_BBPLL_FREQ_OUT_OF_RANGE_TIMEOUT_INTERRUPT, [5] MASK_BBPLL_FREQ_OUT_OF_RANGE_LO_INTERRUPT, [4] MASK_BBPLL_FREQ_OUT_OF_RANGE_HI_INTERRUPT, [3] MASK_BBPLL_TUNE_OUT_OF_RANGE_LO_INTERRUPT, [2] MASK_BBPLL_TUNE_OUT_OF_RANGE_HI_INTERRUPT, [1] MASK_BBPLL_COARSE_OUT_OF_RANGE_LO_INTERRUPT, [0] MASK_BBPLL_COARSE_OUT_OF_RANGE_HI_INTERRUPT
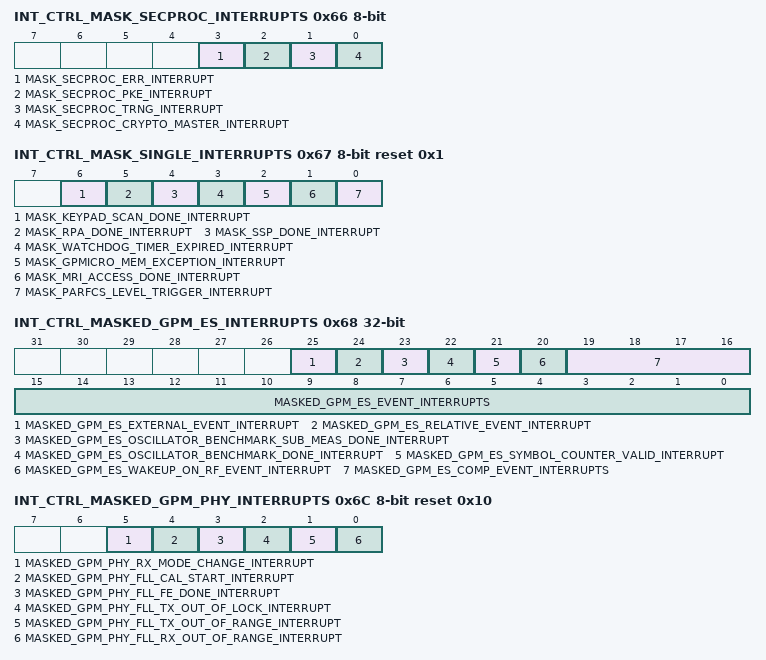
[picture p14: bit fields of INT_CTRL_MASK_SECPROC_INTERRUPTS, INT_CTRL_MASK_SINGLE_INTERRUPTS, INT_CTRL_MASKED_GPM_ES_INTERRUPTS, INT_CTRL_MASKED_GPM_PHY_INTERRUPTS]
0x66 INT_CTRL_MASK_SECPROC_INTERRUPTS
  [3] MASK_SECPROC_ERR_INTERRUPT — masks the interrupt triggered when the internal DMA runs into a memory bus error
  [2] MASK_SECPROC_PKE_INTERRUPT — masks the interrupt triggered by the Public Key submodule, i.e. the asymmetric cryptographic operations engine
  [1] MASK_SECPROC_TRNG_INTERRUPT — masks the interrupt triggered by the NDRNG submodule, i.e. the Non-Deterministic Random Number Generator
  [0] MASK_SECPROC_CRYPTO_MASTER_INTERRUPT — masks the interrupt triggered by the CryptoMaster submodule, i.e. the symmetric cryptographic operations engine
0x67 INT_CTRL_MASK_SINGLE_INTERRUPTS reset 0x1
  [6] MASK_KEYPAD_SCAN_DONE_INTERRUPT — masks the keypad scan done interrupt
  [5] MASK_RPA_DONE_INTERRUPT — masks the rpa done interrupt
  [4] MASK_SSP_DONE_INTERRUPT — masks the ssp done interrupt
  [3] MASK_WATCHDOG_TIMER_EXPIRED_INTERRUPT — masks the watchdog timer expired interrupt
  [2] MASK_GPMICRO_MEM_EXCEPTION_INTERRUPT — masks the mem exception of gpmicro interrupt.
  [1] MASK_MRI_ACCESS_DONE_INTERRUPT — masks the mri write interrupt
  [0] MASK_PARFCS_LEVEL_TRIGGER_INTERRUPT — masks the triggering an interrupt when n bytes were received
0x68 INT_CTRL_MASKED_GPM_ES_INTERRUPTS 32-bit ro
  [25] MASKED_GPM_ES_EXTERNAL_EVENT_INTERRUPT — masked External Event Interrupt
  [24] MASKED_GPM_ES_RELATIVE_EVENT_INTERRUPT — masked es Relative Event Interrupt
  [23] MASKED_GPM_ES_OSCILLATOR_BENCHMARK_SUB_MEAS_DONE_INTERRUPT — masked es oscillator benchmark sub measurement done interrupt
  [22] MASKED_GPM_ES_OSCILLATOR_BENCHMARK_DONE_INTERRUPT — masked es oscillator benchmark interrupt
  [21] MASKED_GPM_ES_SYMBOL_COUNTER_VALID_INTERRUPT — masked es symbol counter interrupt
  [20] MASKED_GPM_ES_WAKEUP_ON_RF_EVENT_INTERRUPT — masked Wakeup_on_rf Event interrupt
  [19:16] MASKED_GPM_ES_COMP_EVENT_INTERRUPTS — masked Comparator Event interrupts
  [15:0] MASKED_GPM_ES_EVENT_INTERRUPTS — masked Event Interrupts
0x6C INT_CTRL_MASKED_GPM_PHY_INTERRUPTS ro reset 0x10
  [5] MASKED_GPM_PHY_RX_MODE_CHANGE_INTERRUPT — masked interrupt for rx_mode changes
  [4] MASKED_GPM_PHY_FLL_CAL_START_INTERRUPT — masked interrupt for the fll fp out of range event
  [3] MASKED_GPM_PHY_FLL_FE_DONE_INTERRUPT — masked interrupt for the fll fp out of range event
  [2] MASKED_GPM_PHY_FLL_TX_OUT_OF_LOCK_INTERRUPT — masked interrupt for the fll tx_out of lock event
  [1] MASKED_GPM_PHY_FLL_TX_OUT_OF_RANGE_INTERRUPT — masked interrupt for the fll tx out of range event
  [0] MASKED_GPM_PHY_FLL_RX_OUT_OF_RANGE_INTERRUPT — masked interrupt for the fll rx out of range event
0x70 INT_CTRL_MASKED_GPM_TRC_INTERRUPTS[0] ro
  [5] MASKED_GPM_TRC_MSG_REQ_WHILE_BUSY_INTERRUPT, [4] MASKED_GPM_TRC_TX_DONE_INTERRUPT, [3] MASKED_GPM_TRC_PHY_TRANSITION_NOT_DONE_INTERRUPT, [2] MASKED_GPM_TRC_TX_ACK_STARTED_INTERRUPT, [1] MASKED_GPM_TRC_TX_STARTED_INTERRUPT, [0] MASKED_GPM_TRC_PBM_FULL_INTERRUPT
0x71 INT_CTRL_MASKED_GPM_TRC_INTERRUPTS[1] ro
  [n] MASKED_GPM_TRC_CAL_DONE_CH{n}_INTERRUPT (n=0..5), [5:0] MASKED_GPM_TRC_CAL_DONE_INTERRUPTS
0x72 INT_CTRL_MASKED_GPM_TRC_INTERRUPTS[2] ro
  [n] MASKED_GPM_TRC_RX_WINDOW_DONE_CH{n}_INTERRUPT (n=0..5), [5:0] MASKED_GPM_TRC_RX_WINDOW_DONE_INTERRUPTS
0x74 INT_CTRL_MASKED_ES_INTERRUPTS 32-bit ro
  [25] MASKED_ES_EXTERNAL_EVENT_INTERRUPT — masked External Event Interrupt
  [24] MASKED_ES_RELATIVE_EVENT_INTERRUPT
  [23] MASKED_ES_OSCILLATOR_BENCHMARK_SUB_MEAS_DONE_INTERRUPT
  [22] MASKED_ES_OSCILLATOR_BENCHMARK_DONE_INTERRUPT — masked es oscillator benchmark interrupt
  [21] MASKED_ES_SYMBOL_COUNTER_VALID_INTERRUPT — masked es symbol counter interrupt
  [20] MASKED_ES_WAKEUP_ON_RF_EVENT_INTERRUPT — masked Wakeup_on_rf Event interrupt
  [19:16] MASKED_ES_COMP_EVENT_INTERRUPTS — masked Comparator Event interrupts
  [15:0] MASKED_ES_EVENT_INTERRUPTS — masked Event Interrupts
0x78 INT_CTRL_MASKED_DMAS_INTERRUPTS[0] ro
  [n] MASKED_DMAS_BUFFER_ALMOST_COMPLETE_{n}_INTERRUPT (n=0..7)
0x79 INT_CTRL_MASKED_DMAS_INTERRUPTS[1] ro
  [n] MASKED_DMAS_BUFFER_COMPLETE_{n}_INTERRUPT (n=0..7)
0x7A INT_CTRL_MASKED_DMAS_INTERRUPTS[2] ro
  [0] MASKED_DMAS_CPY_ERR_INTERRUPT
0x7B INT_CTRL_MASKED_QTA_INTERRUPTS ro
  [4] MASKED_QTA_QUEUE_FULL_INTERRUPT, [n] MASKED_QTA_SCH{n}_EMPTY_INTERRUPT (n=0..3)
0x7C INT_CTRL_MASKED_TRC_INTERRUPTS[0] ro
  [5] MASKED_TRC_MSG_REQ_WHILE_BUSY_INTERRUPT, [4] MASKED_TRC_TX_DONE_INTERRUPT, [3] MASKED_TRC_PHY_TRANSITION_NOT_DONE_INTERRUPT, [2] MASKED_TRC_TX_ACK_STARTED_INTERRUPT, [1] MASKED_TRC_TX_STARTED_INTERRUPT, [0] MASKED_TRC_PBM_FULL_INTERRUPT
0x7D INT_CTRL_MASKED_TRC_INTERRUPTS[1] ro
  [n] MASKED_TRC_CAL_DONE_CH{n}_INTERRUPT (n=0..5), [5:0] MASKED_TRC_CAL_DONE_INTERRUPTS
0x7E INT_CTRL_MASKED_TRC_INTERRUPTS[2] ro
  [n] MASKED_TRC_RX_WINDOW_DONE_CH{n}_INTERRUPT (n=0..5), [5:0] MASKED_TRC_RX_WINDOW_DONE_INTERRUPTS
0x7F INT_CTRL_MASKED_PARBLE_INTERRUPTS ro reset 0x1
  [1] MASKED_PARBLE_PACKET_DONE_INTERRUPT
  [0] MASKED_PARBLE_LEVEL_TRIGGER_INTERRUPT — triggering an interrupt when n bytes were received
0x80 INT_CTRL_MASKED_STBC_INTERRUPTS ro
  [2] MASKED_STBC_VLT_STATUS_INTERRUPT — masked standby controller vlt_status interrupt
  [1] MASKED_STBC_ACTIVE_INTERRUPT — masked standby controller Active state interrupt
  [0] MASKED_STBC_PORD_INTERRUPT — masked standby controller event power on reset detected interrupt
0x81 INT_CTRL_MASKED_I2CM_INTERRUPTS ro
  [2] MASKED_I2CM_CLK_SYNC_INTERRUPT — masked I2C master clock synchronization slave wait interrupt
  [1] MASKED_I2CM_ARB_LOST_INTERRUPT — masked I2C master arbitration lost interrupt
  [0] MASKED_I2CM_DONE_INTERRUPT — masked I2C master done interrupt
0x82 INT_CTRL_MASKED_RCI_INTERRUPTS 16-bit ro
  [9] MASKED_RCI_BLE_DATA_CNF_INTERRUPT, [8] MASKED_RCI_BLE_CONN_RSP_IND_INTERRUPT, [7] MASKED_RCI_BLE_CONN_REQ_IND_INTERRUPT, [6] MASKED_RCI_BLE_ADV_IND_INTERRUPT, [5] MASKED_RCI_BLE_DATA_IND_INTERRUPT, [n+1] MASKED_RCI_DATA_CNF_{n}_INTERRUPT (n=0..3), [4:1] MASKED_RCI_DATA_CNF_INTERRUPTS, [0] MASKED_RCI_DATA_IND_INTERRUPT
0x84 INT_CTRL_MASKED_PHY_INTERRUPTS ro
  [5] MASKED_PHY_RX_MODE_CHANGE_INTERRUPT — masked interrupt for rx_mode changes
  [4] MASKED_PHY_FLL_CAL_START_INTERRUPT — masked interrupt for the fll fp out of range event
  [3] MASKED_PHY_FLL_FE_DONE_INTERRUPT — masked interrupt for the fll fp out of range event
  [2] MASKED_PHY_FLL_TX_OUT_OF_LOCK_INTERRUPT — masked interrupt for the fll tx_out of lock event
  [1] MASKED_PHY_FLL_TX_OUT_OF_RANGE_INTERRUPT — masked interrupt for the fll tx out of range event
  [0] MASKED_PHY_FLL_RX_OUT_OF_RANGE_INTERRUPT — masked interrupt for the fll rx out of range event
0x85 INT_CTRL_MASKED_GPIO_INTERRUPTS ro
  [n] MASKED_GPIO_EXTI{n}_INTERRUPT (n=0..7) — masked gpio interrupts for exti {n} of the selected port
0x86 INT_CTRL_MASKED_SPIM_INTERRUPTS ro
  [3] MASKED_SPIM_RX_OVERRUN_INTERRUPT — masked SPI master RX buffer overrun interrupt
  [2] MASKED_SPIM_RX_NOT_EMPTY_INTERRUPT — masked SPI master RX buffer not empty interrupt
  [1] MASKED_SPIM_TX_NOT_FULL_INTERRUPT — masked SPI master TX buffer empty interrupt
  [0] MASKED_SPIM_NOT_BUSY_INTERRUPT — masked SPI master transfer not busy interrupt
0x87 INT_CTRL_MASKED_SPISL_INTERRUPTS ro
  [4] MASKED_SPISL_TX_EMPTY_INTERRUPT — masked SPI slave TX empty interrupt
  [3] MASKED_SPISL_RX_OVERRUN_INTERRUPT — masked SPI slave RX buffer overrun interrupt
  [2] MASKED_SPISL_TX_UNDERRUN_INTERRUPT — masked SPI slave TX buffer underrun interrupt
  [1] MASKED_SPISL_RX_NOT_EMPTY_INTERRUPT — masked SPI slave RX buffer not empty interrupt
  [0] MASKED_SPISL_TX_NOT_FULL_INTERRUPT — masked SPI slave TX buffer empty interrupt
0x88 INT_CTRL_MASKED_IPCGPM2X_INTERRUPTS[0] ro
  [7] MASKED_IPCGPM2X_STAT_INTERRUPT — masked gpmicro status interrupt
  [6] MASKED_IPCGPM2X_UNEXPECTED_COND_INTERRUPT — masked gpmicro unexpected condition interrupt
  [5] MASKED_IPCGPM2X_ERROR_INTERRUPT — masked gpmicro error interrupt
  [4] MASKED_IPCGPM2X_CMD_PROCESSED_INTERRUPT — Indicates that an internal cmd is processed
  [3] MASKED_IPCGPM2X_FLAG_D_INTERRUPT — masked inter processor communication source interrupt (gpm 2 ...)
  [2] MASKED_IPCGPM2X_FLAG_C_INTERRUPT — masked inter processor communication source interrupt (gpm 2 ...)
  [1] MASKED_IPCGPM2X_FLAG_B_INTERRUPT — masked inter processor communication source interrupt (gpm 2 ...)
  [0] MASKED_IPCGPM2X_FLAG_A_INTERRUPT — masked inter processor communication source interrupt (gpm 2 ...)
0x89 INT_CTRL_MASKED_IPCGPM2X_INTERRUPTS[1] ro
  [7] MASKED_IPCGPM2X_LAST_CONN_EVENT_CNT_INTERRUPT — Indicates that a connection ble event has reached its last_sch_event_cnt (if enabled)
  [6] MASKED_IPCGPM2X_EVENT_PROCESSED_INTERRUPT — Indicates that a ble event has been processed
  [5] MASKED_IPCGPM2X_SUBEV_DONE_INTERRUPT — Indicates that a subevent has been processed
  [4] MASKED_IPCGPM2X_CONN_REQ_TX_INTERRUPT — Indicates that a CONN_REQ frame is sent
  [3] MASKED_IPCGPM2X_SCAN_REQ_TX_INTERRUPT — Indicates that a SCAN_REQ frame is sent
  [2] MASKED_IPCGPM2X_SCAN_RSP_TX_INTERRUPT — Indicates a scan response is sent
  [1] MASKED_IPCGPM2X_SCAN_REQ_RX_INTERRUPT — Indicates a scan request has been received
  [0] MASKED_IPCGPM2X_ADV_TX_INTERRUPT — Indicates a frame is sent during an advertising event
0x8A INT_CTRL_MASKED_IPCGPM2X_INTERRUPTS[2] ro
  [0] MASKED_IPCGPM2X_EVENT_SKIPPED_INTERRUPT — Indicates that a ble event has been skipped
0x8B INT_CTRL_MASKED_IPCX2GPM_INTERRUPTS ro
  [4] MASKED_IPCX2GPM_CMD_INTERRUPT — Indicates that a cmd is available to be processed
  [3] MASKED_IPCX2GPM_FLAG_D_INTERRUPT
  [2] MASKED_IPCX2GPM_FLAG_C_INTERRUPT
  [1] MASKED_IPCX2GPM_FLAG_B_INTERRUPT
  [0] MASKED_IPCX2GPM_FLAG_A_INTERRUPT
0x8C INT_CTRL_MASKED_IPCINT2X_INTERRUPTS ro
  [3] MASKED_IPCINT2X_FLAG_D_INTERRUPT — masked inter processor communication source interrupt (int 2 ...)
  [2] MASKED_IPCINT2X_FLAG_C_INTERRUPT — masked inter processor communication source interrupt (int 2 ...)
  [1] MASKED_IPCINT2X_FLAG_B_INTERRUPT — masked inter processor communication source interrupt (int 2 ...)
  [0] MASKED_IPCINT2X_FLAG_A_INTERRUPT — masked inter processor communication source interrupt (int 2 ...)
0x8D INT_CTRL_MASKED_IPCX2INT_INTERRUPTS ro
  [3] MASKED_IPCX2INT_FLAG_D_INTERRUPT — masked inter processor communication source interrupt (... 2 int)
  [2] MASKED_IPCX2INT_FLAG_C_INTERRUPT — masked inter processor communication source interrupt (... 2 int)
  [1] MASKED_IPCX2INT_FLAG_B_INTERRUPT — masked inter processor communication source interrupt (... 2 int)
  [0] MASKED_IPCX2INT_FLAG_A_INTERRUPT — masked inter processor communication source interrupt (... 2 int)
0x8E INT_CTRL_MASKED_IPCEXT2X_INTERRUPTS ro
  [3] MASKED_IPCEXT2X_FLAG_D_INTERRUPT — masked inter processor communication source interrupt (ext 2 ...)
  [2] MASKED_IPCEXT2X_FLAG_C_INTERRUPT — masked inter processor communication source interrupt (ext 2 ...)
  [1] MASKED_IPCEXT2X_FLAG_B_INTERRUPT — masked inter processor communication source interrupt (ext 2 ...)
  [0] MASKED_IPCEXT2X_FLAG_A_INTERRUPT — masked inter processor communication source interrupt (ext 2 ...)
0x8F INT_CTRL_MASKED_IPCX2EXT_INTERRUPTS ro
  [3] MASKED_IPCX2EXT_FLAG_D_INTERRUPT — masked inter processor communication source interrupt (... 2 ext)
  [2] MASKED_IPCX2EXT_FLAG_C_INTERRUPT — masked inter processor communication source interrupt (... 2 ext)
  [1] MASKED_IPCX2EXT_FLAG_B_INTERRUPT — masked inter processor communication source interrupt (... 2 ext)
  [0] MASKED_IPCX2EXT_FLAG_A_INTERRUPT — masked inter processor communication source interrupt (... 2 ext)
0x90 INT_CTRL_MASKED_I2CSL_INTERRUPTS ro
  [5] MASKED_I2CSL_SLAD_INTERRUPT — masked I2C SLAD event occurred interrupt
  [4] MASKED_I2CSL_STOP_INTERRUPT — masked I2C STOP event occurred interrupt
  [3] MASKED_I2CSL_START_INTERRUPT — masked I2C START event occurred interrupt
  [2] MASKED_I2CSL_TX_STRETCH_INTERRUPT — masked TX stretch interrupt.
  [1] MASKED_I2CSL_RX_NOT_EMPTY_INTERRUPT — masked RX buffer not empty interrupt
  [0] MASKED_I2CSL_TX_NOT_FULL_INTERRUPT — masked TX buffer not full interrupt.
0x94 INT_CTRL_MASKED_PWMS_INTERRUPTS[0] ro
  [n] MASKED_PWMS_PWM{n}_THRESHOLD_MATCH_INTERRUPT (n=0..7) — masked PWM threshold_match interrupt of pwm{n}
0x95 INT_CTRL_MASKED_PWMS_INTERRUPTS[1] ro
  [7] MASKED_PWMS_TIMESTAMP1_NOT_EMPTY_INTERRUPT — masked PWM timestamp1 not empty interrupt
  [7:6] MASKED_PWMS_TIMESTAMP_NOT_EMPTY_INTERRUPT[0] — masked PWM timestamp not empty interrupt
  [6] MASKED_PWMS_TIMESTAMP0_NOT_EMPTY_INTERRUPT — masked PWM timestamp0 not empty interrupt
  [n+2] MASKED_PWMS_TIMESTAMP{n}_OVERRUN_INTERRUPT (n=0..3) — masked PWM timestamp{n} overrun interrupt
  [5:2] MASKED_PWMS_TIMESTAMP_OVERRUN_INTERRUPT — masked PWM timestamp overrun interrupt
  [1] MASKED_PWMS_NEXT_THRESHOLD_NOT_FULL_INTERRUPT — masked PWM next threshold not full interrupt
  [0] MASKED_PWMS_NEXT_THRESHOLD_UNDERRUN_INTERRUPT — masked PWM next threshold underrun interrupt
0x96 INT_CTRL_MASKED_PWMS_INTERRUPTS[2] ro
  [1] MASKED_PWMS_TIMESTAMP3_NOT_EMPTY_INTERRUPT — masked PWM timestamp3 not empty interrupt
  [1:0] MASKED_PWMS_TIMESTAMP_NOT_EMPTY_INTERRUPT[1] — masked PWM timestamp not empty interrupt
  [0] MASKED_PWMS_TIMESTAMP2_NOT_EMPTY_INTERRUPT — masked PWM timestamp2 not empty interrupt
0x98 INT_CTRL_MASKED_ADCIF_INTERRUPTS 16-bit ro
  [8] MASKED_ADCIF_AWD_BELOW_MINIMUM_INTERRUPT — masked analog watchdog value below minimum interrupt
  [7] MASKED_ADCIF_AWD_ABOVE_MAXIMUM_INTERRUPT — masked analog watchdog value above maximum interrupt
  [6] MASKED_ADCIF_OVERVOLTAGE_INTERRUPT — masked fifo overvoltage interrupt
  [5] MASKED_ADCIF_CYCLE_DONE_INTERRUPT — masked cycle done interrupt
  [4] MASKED_ADCIF_FIFO_OVERRUN_INTERRUPT — masked fifo overrun interrupt
  [3] MASKED_ADCIF_FIFO_NOT_EMPTY_INTERRUPT — masked fifo not empty interrupt
  [2] MASKED_ADCIF_BUFFER_C_UPDATED_INTERRUPT — masked buffer c updated interrupt
  [1] MASKED_ADCIF_BUFFER_B_UPDATED_INTERRUPT — masked buffer b updated interrupt
  [0] MASKED_ADCIF_BUFFER_A_UPDATED_INTERRUPT — masked buffer a updated interrupt
0x9A INT_CTRL_MASKED_UART_0_INTERRUPTS ro
  [5] MASKED_UART_0_RX_FRAMING_ERROR_INTERRUPT — masked RX framing error interrupt.
  [4] MASKED_UART_0_RX_PARITY_ERROR_INTERRUPT — masked RX parity error interrupt.
  [3] MASKED_UART_0_RX_OVERRUN_INTERRUPT — masked RX overrun interrupt.
  [2] MASKED_UART_0_RX_NOT_EMPTY_INTERRUPT — masked RX not empty interrupt.
  [1] MASKED_UART_0_TX_NOT_FULL_INTERRUPT — masked TX not full interrupt.
  [0] MASKED_UART_0_TX_NOT_BUSY_INTERRUPT — masked TX not busy interrupt.
0x9B INT_CTRL_MASKED_UART_1_INTERRUPTS ro
  [5] MASKED_UART_1_RX_FRAMING_ERROR_INTERRUPT — masked RX framing error interrupt.
  [4] MASKED_UART_1_RX_PARITY_ERROR_INTERRUPT — masked RX parity error interrupt.
  [3] MASKED_UART_1_RX_OVERRUN_INTERRUPT — masked RX overrun interrupt.
  [2] MASKED_UART_1_RX_NOT_EMPTY_INTERRUPT — masked RX not empty interrupt.
  [1] MASKED_UART_1_TX_NOT_FULL_INTERRUPT — masked TX not full interrupt.
  [0] MASKED_UART_1_TX_NOT_BUSY_INTERRUPT — masked TX not busy interrupt.
0x9C INT_CTRL_MASKED_TIMERS_INTERRUPTS ro
  [n] MASKED_TIMERS_TMR{n}_WRAP_INTERRUPT (n=0..4)
0x9D INT_CTRL_MASKED_IR_INTERRUPTS ro
  [3] MASKED_IR_INDEX_MATCH_INTERRUPT, [2] MASKED_IR_SEQUENCE_DONE_INTERRUPT, [1] MASKED_IR_SEQUENCE_REPEAT_INTERRUPT, [0] MASKED_IR_SEQUENCE_START_INTERRUPT
0x9E INT_CTRL_MASKED_ASP_INTERRUPTS ro
  [1] MASKED_ASP_DATASTREAM_1_VALID_INTERRUPT, [0] MASKED_ASP_DATASTREAM_0_VALID_INTERRUPT
0x9F INT_CTRL_MASKED_I2SM_INTERRUPTS ro
  [1] MASKED_I2SM_RX_NOT_EMPTY_INTERRUPT, [0] MASKED_I2SM_TX_NOT_FULL_INTERRUPT
0xA0 INT_CTRL_MASKED_BBPLL_INTERRUPTS 16-bit ro
  [8] MASKED_BBPLL_OUT_OF_LOCK_INTERRUPT, [7] MASKED_BBPLL_IN_LOCK_INTERRUPT, [6] MASKED_BBPLL_FREQ_OUT_OF_RANGE_TIMEOUT_INTERRUPT, [5] MASKED_BBPLL_FREQ_OUT_OF_RANGE_LO_INTERRUPT, [4] MASKED_BBPLL_FREQ_OUT_OF_RANGE_HI_INTERRUPT, [3] MASKED_BBPLL_TUNE_OUT_OF_RANGE_LO_INTERRUPT, [2] MASKED_BBPLL_TUNE_OUT_OF_RANGE_HI_INTERRUPT, [1] MASKED_BBPLL_COARSE_OUT_OF_RANGE_LO_INTERRUPT, [0] MASKED_BBPLL_COARSE_OUT_OF_RANGE_HI_INTERRUPT
0xA2 INT_CTRL_MASKED_SECPROC_INTERRUPTS ro
  [3] MASKED_SECPROC_ERR_INTERRUPT — masked interrupt triggered when the internal DMA runs into a memory bus error
  [2] MASKED_SECPROC_PKE_INTERRUPT — masked interrupt triggered by the Public Key submodule, i.e. the asymmetric cryptographic operations engine
  [1] MASKED_SECPROC_TRNG_INTERRUPT — masked interrupt triggered by the NDRNG submodule, i.e. the Non-Deterministic Random Number Generator
  [0] MASKED_SECPROC_CRYPTO_MASTER_INTERRUPT — masked interrupt triggered by the CryptoMaster submodule, i.e. the symmetric cryptographic operations engine
0xA3 INT_CTRL_MASKED_SINGLE_INTERRUPTS ro reset 0x1
  [6] MASKED_KEYPAD_SCAN_DONE_INTERRUPT
  [5] MASKED_RPA_DONE_INTERRUPT
  [4] MASKED_SSP_DONE_INTERRUPT
  [3] MASKED_WATCHDOG_TIMER_EXPIRED_INTERRUPT
  [2] MASKED_GPMICRO_MEM_EXCEPTION_INTERRUPT — masked mem exception of gpmicro interrupt.
  [1] MASKED_MRI_ACCESS_DONE_INTERRUPT — masked mri write interrupt
  [0] MASKED_PARFCS_LEVEL_TRIGGER_INTERRUPT — masked triggering an interrupt when n bytes were received
